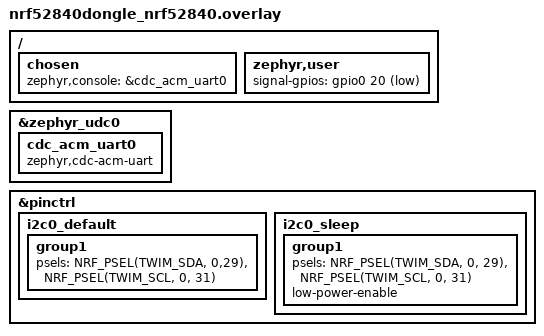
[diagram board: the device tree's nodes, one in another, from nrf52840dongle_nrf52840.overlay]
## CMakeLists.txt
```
#
# Copyright (c) 2018 Nordic Semiconductor
#
# SPDX-License-Identifier: LicenseRef-Nordic-5-Clause
#
cmake_minimum_required(VERSION 3.20.0)

set(PM_STATIC_YML_FILE
  ${CMAKE_CURRENT_SOURCE_DIR}/boards/pm_static_${BOARD}.yml
  )

find_package(Zephyr REQUIRED HINTS $ENV{ZEPHYR_BASE})
project(NONE)

target_sources(app PRIVATE src/max30102.c)

# NORDIC SDK APP START
target_sources(app PRIVATE
  src/main.c
)



# Preinitialization related to Thingy:53 DFU
target_sources_ifdef(CONFIG_BOARD_THINGY53_NRF5340_CPUAPP app PRIVATE  boards/thingy53.c)
target_sources_ifdef(CONFIG_BOARD_THINGY53_NRF5340_CPUAPP_NS app PRIVATE  boards/thingy53.c)

# NORDIC SDK APP END

zephyr_library_include_directories(.)
```

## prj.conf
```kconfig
#
# Copyright (c) 2018 Nordic Semiconductor
#
# SPDX-License-Identifier: LicenseRef-Nordic-5-Clause
#

# Enable the UART driver


# Make sure printk is printing to the UART console

CONFIG_USB_DEVICE_STACK=y
CONFIG_USB_DEVICE_PRODUCT="Zephyr USB console sample"

CONFIG_SERIAL=y
CONFIG_CONSOLE=y
CONFIG_UART_CONSOLE=y
CONFIG_UART_LINE_CTRL=y

#CONFIG_STDOUT_CONSOLE=y
#CONFIG_LOG=y
CONFIG_I2C=y

CONFIG_I2C=y
CONFIG_HEAP_MEM_POOL_SIZE=2048

CONFIG_BT=y
CONFIG_BT_PERIPHERAL=y
CONFIG_BT_DEVICE_NAME="Nordic_UART_Service"
CONFIG_BT_DEVICE_APPEARANCE=833
CONFIG_BT_MAX_CONN=1
CONFIG_BT_MAX_PAIRED=1
CONFIG_BT_NUS_SECURITY_ENABLED=n

# Enable the NUS service
CONFIG_BT_NUS=y

# Enable bonding
CONFIG_BT_SETTINGS=y
CONFIG_FLASH=y
CONFIG_FLASH_PAGE_LAYOUT=y
CONFIG_FLASH_MAP=y
CONFIG_NVS=y
CONFIG_SETTINGS=y


# This example requires more workqueue stack
CONFIG_SYSTEM_WORKQUEUE_STACK_SIZE=2048


# Config logger
CONFIG_LOG=y
CONFIG_USE_SEGGER_RTT=y
CONFIG_LOG_BACKEND_RTT=y
CONFIG_LOG_BACKEND_UART=y

CONFIG_ASSERT=y
```

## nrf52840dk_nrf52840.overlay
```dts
&pinctrl {
	i2c0_default: i2c0_default {
		group1 {
			psels = <NRF_PSEL(TWIM_SDA, 0,27)>,
				<NRF_PSEL(TWIM_SCL, 0, 26)>;
		};
	};

	i2c0_sleep: i2c0_sleep {
		group1 {
			psels = <NRF_PSEL(TWIM_SDA, 0, 27)>,
				<NRF_PSEL(TWIM_SCL, 0, 26)>;
			low-power-enable;
		};
	};
};
```

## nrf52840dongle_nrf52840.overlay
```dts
// To get started, press Ctrl+Space to bring up the completion menu and view the available nodes.

// You can also use the buttons in the sidebar to perform actions on nodes.
// Actions currently available include:

// * Enabling / disabling the node
// * Adding the bus to a bus
// * Removing the node
// * Connecting ADC channels

// For more help, browse the DeviceTree documentation at https://docs.zephyrproject.org/latest/guides/dts/index.html
// You can also visit the nRF DeviceTree extension documentation at https://nrfconnect.github.io/vscode-nrf-connect/devicetree/nrfdevicetree.html
/ {
	chosen {
		zephyr,console = &cdc_acm_uart0;
	};
	zephyr,user {
        signal-gpios = <&gpio0 20 (GPIO_PULL_UP | GPIO_ACTIVE_LOW)>;
    };
};

&zephyr_udc0 {
	cdc_acm_uart0: cdc_acm_uart0 {
		compatible = "zephyr,cdc-acm-uart";
	};
};


&pinctrl {
	i2c0_default: i2c0_default {
		group1 {
			psels = <NRF_PSEL(TWIM_SDA, 0,29)>,
				<NRF_PSEL(TWIM_SCL, 0, 31)>;
		};
	};

	i2c0_sleep: i2c0_sleep {
		group1 {
			psels = <NRF_PSEL(TWIM_SDA, 0, 29)>,
				<NRF_PSEL(TWIM_SCL, 0, 31)>;
			low-power-enable;
		};
	};
};
```

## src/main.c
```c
#include <zephyr.h>
#include <zephyr/types.h>
#include <zephyr/kernel.h>

#include <zephyr/device.h>
#include <zephyr/devicetree.h>
#include <soc.h>

#include <zephyr/bluetooth/bluetooth.h>
#include <zephyr/bluetooth/uuid.h>
#include <zephyr/bluetooth/gatt.h>
#include <zephyr/bluetooth/hci.h>

#include <bluetooth/services/nus.h>
#include <zephyr/settings/settings.h>
#include <zephyr/drivers/uart.h>
#include <zephyr/usb/usb_device.h>
#include <stdio.h>

#include <zephyr/logging/log.h>
#include "max30102.h"

#define LOG_MODULE_NAME bt_hr_sensor
LOG_MODULE_REGISTER(LOG_MODULE_NAME);

#define STACKSIZE CONFIG_BT_NUS_THREAD_STACK_SIZE
#define PRIORITY 7

#define DEVICE_NAME CONFIG_BT_DEVICE_NAME
#define DEVICE_NAME_LEN	(sizeof(DEVICE_NAME) - 1)


#define ZEPHYR_USER_NODE DT_PATH(zephyr_user)

static K_SEM_DEFINE(ble_init_ok, 0, 1);

K_FIFO_DEFINE(ppg_items);
K_SEM_DEFINE(sem_initialized_max30102, 0, 1);
K_SEM_DEFINE(sem_interruptmax30102, 0, 1);

const struct device *gpio0Port;	
struct gpio_callback interrupt_max30102;

static struct bt_conn *current_conn;
//static struct bt_conn *auth_conn;

static const struct bt_data ad[] = {
	BT_DATA_BYTES(BT_DATA_FLAGS, (BT_LE_AD_GENERAL | BT_LE_AD_NO_BREDR)),
	BT_DATA(BT_DATA_NAME_COMPLETE, DEVICE_NAME, DEVICE_NAME_LEN),
};

static const struct bt_data sd[] = {
	BT_DATA_BYTES(BT_DATA_UUID128_ALL, BT_UUID_NUS_VAL),
};

static const struct gpio_dt_spec signal = GPIO_DT_SPEC_GET(ZEPHYR_USER_NODE, signal_gpios);
BUILD_ASSERT(DT_NODE_HAS_COMPAT(DT_CHOSEN(zephyr_console), zephyr_cdc_acm_uart),
	     "Console device is not ACM CDC UART device");

static void connected(struct bt_conn *conn, uint8_t err)
{
	char addr[BT_ADDR_LE_STR_LEN];

	if (err) {
		LOG_ERR("Connection failed (err %u)", err);
		return;
	}

	bt_addr_le_to_str(bt_conn_get_dst(conn), addr, sizeof(addr));
	LOG_INF("Connected %s", addr);

	current_conn = bt_conn_ref(conn);	
}

static void disconnected(struct bt_conn *conn, uint8_t reason)
{
	char addr[BT_ADDR_LE_STR_LEN];

	bt_addr_le_to_str(bt_conn_get_dst(conn), addr, sizeof(addr));

	LOG_INF("Disconnected: %s (reason %u)", addr, reason);
	sys_reboot();
}



BT_CONN_CB_DEFINE(conn_callbacks) = {
	.connected    = connected,
	.disconnected = disconnected,

};

static void bt_receive_cb(struct bt_conn *conn, const uint8_t *const data,
			  uint16_t len)
{
	(void)conn;
	LOG_INF("Received data ");
}

static struct bt_nus_cb nus_cb = {
	.received = bt_receive_cb,
};

typedef struct {
    void *fifo_reserved;   /* 1st word reserved for use by FIFO */
    ppg_item_t ppgitem;
} fifo_item_t;

void max30102isr(const struct device *dev, struct gpio_callback *cb, uint32_t pins) {	
	k_sem_give(&sem_interruptmax30102);		
}

void attachinterrupt(void) {
	
	__ASSERT(device_is_ready(signal.port), "custom device not ready");
	gpio_pin_configure_dt(&signal, GPIO_INPUT);
	gpio_pin_interrupt_configure_dt(&signal, GPIO_INT_EDGE_TO_ACTIVE);
	gpio_init_callback(&interrupt_max30102, max30102isr, BIT(signal.pin));
	gpio_add_callback(signal.port, &interrupt_max30102);	
}


void main(void)
{	
	//const struct device *dev = DEVICE_DT_GET(DT_CHOSEN(zephyr_console));
	//uint32_t dtr = 0;

	if (usb_enable(NULL)) {
		return;
	}

	/* Poll if the DTR flag was set */
	// while (!dtr) {
	// 	uart_line_ctrl_get(dev, UART_LINE_CTRL_DTR, &dtr);
	// 	/* Give CPU resources to low priority threads. */
	// 	k_sleep(K_MSEC(100));
	// }


	int err = 0;	

	err = bt_enable(NULL);	

	LOG_INF("Bluetooth initialized");	

	if (IS_ENABLED(CONFIG_SETTINGS)) {
		settings_load();
	}

	err = bt_nus_init(&nus_cb);
	if (err) {
		LOG_ERR("Failed to initialize UART service (err: %d)", err);
		return;
	}

	err = bt_le_adv_start(BT_LE_ADV_CONN, ad, ARRAY_SIZE(ad), sd,
			      ARRAY_SIZE(sd));
	if (err) {
		LOG_ERR("Advertising failed to start (err %d)", err);
		return;
	}


	LOG_INF("interrupt-attached");

	if(max30102_init()) {
		LOG_ERR("could not initialize");
		k_sleep(K_FOREVER);		
	}	
	attachinterrupt();
	uint8_t max_read_state = max30102_interrupt_state(); //clear interrupt;

	LOG_INF("max initialized, read state:%i", max_read_state);
	
	
	k_sem_give(&sem_initialized_max30102);

	k_sem_give(&ble_init_ok);
	LOG_INF("bt-enabled");

	for (;;) {		
		k_sleep(K_MSEC(2000));
		LOG_INF("alive");
	}
}

void nus_fifo_service(void)
{	
	/* Don't go any further until BLE is initialized */
	k_sem_take(&ble_init_ok, K_FOREVER);
	char buffer[sizeof(ppg_item_t)];
	
	for (;;) {
		
		fifo_item_t *package;
		package = k_fifo_get(&ppg_items, K_FOREVER);
		ppg_item_t ppgitem = package->ppgitem;	
		memcpy(buffer, (uint8_t*)&ppgitem, sizeof(ppg_item_t));
		if (bt_nus_send(NULL, buffer, sizeof(ppg_item_t))) {
			LOG_WRN("Failed to send data over BLE connection");
		} else {			
			LOG_INF("send ppg ir=%d, red=%d", ppgitem.ir, ppgitem.red);
		}
		k_free(package);
	}
}

void max30102read(void) {	
	k_sem_take(&sem_initialized_max30102, K_FOREVER);
	
	uint8_t amount_samples;
	uint8_t isrstate;
	ppg_item_t buffer[32]; //maximum amount for ic
	
	while (1) {		
		k_sem_take(&sem_interruptmax30102, K_MSEC(5000));
		isrstate = max30102_interrupt_state();
		if (isrstate != 0b10000000) {
			LOG_WRN("unexpected max30102int: %d", isrstate);	
		} 
		amount_samples = GetSamplesAvailable();		
		
		max30102data(buffer, amount_samples);
		
		for (int i = 0; i < amount_samples; i++)
		{			
			fifo_item_t *toqueue = k_malloc(sizeof(fifo_item_t));
			toqueue->ppgitem = buffer[i];			
			k_fifo_put(&ppg_items, toqueue);
		} 			
	}
}

K_THREAD_DEFINE(max30102_read_thread_id, 1024, max30102read, NULL, NULL,
		NULL, 7, 0, 0);

K_THREAD_DEFINE(nus_fifo_service_id, STACKSIZE, nus_fifo_service, NULL, NULL,
		NULL, 8, 0, 0);
```

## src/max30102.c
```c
/*
 * Copyright (c) 2017, NXP
 *
 * SPDX-License-Identifier: Apache-2.0
 */
//#define DT_DRV_COMPAT maxim_max30101

#include <zephyr.h>
#include <stdio.h>
#include <logging/log.h>
#include "max30102.h"

#define register_count 9
#define led_channels 1

const struct device *i2c;


max30102_config max30102cfg = {
// 	.i2c_label = DT_INST_PROP(0, label),
 	.i2c_addr = 0x57// DT_INST_REG_ADDR(0),
};



LOG_MODULE_REGISTER(MAX30102, 0);

int GetSamplesAvailable()
{
	uint8_t fifo_wr_ptr;
	uint8_t fifo_rd_ptr;
	int samples_avalable = 0;

	int wr = i2c_reg_read_byte(i2c, max30102cfg.i2c_addr, 0x04, &fifo_wr_ptr);
	int rd = i2c_reg_read_byte(i2c, max30102cfg.i2c_addr, 0x06, &fifo_rd_ptr);
	if(wr || rd) {
		LOG_ERR("max30102 read or write pointer error");
		return 0;
	}

	if (fifo_wr_ptr != fifo_rd_ptr)
	{
		samples_avalable = fifo_wr_ptr - fifo_rd_ptr;
		if (samples_avalable < 0) {
			samples_avalable += 32; // wrap condition>		
		}
	}	
	return samples_avalable;
}

float temperature(void)
{
	uint8_t temperature;
	uint8_t fraction;
	i2c_reg_read_byte(i2c, max30102cfg.i2c_addr, 0x1F, &temperature);
	i2c_reg_read_byte(i2c, max30102cfg.i2c_addr, 0x20, &fraction);
	if (temperature > 0x7F)
	{
		temperature = -0xFF + (temperature - 1);
	}
	// enable temperature
	i2c_reg_write_byte(i2c, max30102cfg.i2c_addr, 0x21, 1);
	return (float)temperature + fraction * 0.0625;
}


int fetch_max30102(uint32_t * samplebuffer, int samplesToTake)
{
	if (samplesToTake == 0) return 0;	
	
	uint32_t fifo_data;
	int num_bytes = 3 * led_channels * samplesToTake; //2 channels, 3 bytes each
	uint8_t buffer[num_bytes];

	/* Read all the active channels for all samples */		 
	if (i2c_burst_read(i2c, max30102cfg.i2c_addr, 0x07, buffer, num_bytes))
	{
		LOG_ERR("could not read sample");
		return 1;
	}
	
	for (uint32_t y = 0; y < (samplesToTake * led_channels); y++)
	{				
		/* Each channel sample is 18-bits */
		fifo_data = (buffer[y*3] << 16) | (buffer[y*3 + 1] << 8) |
					(buffer[y*3 + 2]);
		fifo_data &= MAX30102_FIFO_DATA_MASK;

		samplebuffer[y] = fifo_data;
	}

	return 0;
}

int max30102data(ppg_item_t * ppg_items, int samplesToTake) {
	int buffersize = samplesToTake * led_channels;
	uint32_t buffer[buffersize]; //two led colors
	if(fetch_max30102(buffer, samplesToTake)){
		return 1;
	}
	unsigned int pic = 0; //ppg item count
	for (size_t i = 0; i < buffersize; i+=led_channels)
	{				
		ppg_items[pic].ir = buffer[i];
#if(led_channels > 1)
		ppg_items[pic].red = buffer[i+1];	
#else
		ppg_items[pic].red = 0;	
#endif
		pic++;
	}
	return 0;
}

uint8_t max30102_interrupt_state() {
	uint8_t status;
	i2c_reg_read_byte(i2c, max30102cfg.i2c_addr, 0x00, &status);
	return status;
}

int safewriteconfig(uint8_t reg, uint8_t value) {
	if (i2c_reg_write_byte(i2c, max30102cfg.i2c_addr, reg,value))
	{
		LOG_ERR("couldn't write to 0x%02x", reg);
		return -EIO;
	}
	return 0;
}

int max30102_init()
{
	uint8_t part_id;
	uint8_t mode_cfg;

	/* Get the I2C device */	
	i2c = DEVICE_DT_GET(DT_NODELABEL(i2c0));
	__ASSERT(device_is_ready(i2c), "max30102 device not ready");
	
	

	/* Check the part id to make sure this is MAX30102 */
	if (i2c_reg_read_byte(i2c, max30102cfg.i2c_addr,
						  MAX30102_REG_PART_ID, &part_id))
	{
		LOG_ERR("Could not get Part ID");
		return -EIO;
	}
	if (part_id != MAX30102_PART_ID)
	{
		LOG_ERR("Got Part ID 0x%02x, expected 0x%02x",
				part_id, MAX30102_PART_ID);
		return -EIO;
	}
	else
	{
		LOG_INF("Got Part ID 0x%02x as expected", part_id);
	}

	/* Reset the sensor */
	if (i2c_reg_write_byte(i2c, max30102cfg.i2c_addr,
						   MAX30102_REG_MODE_CFG,
						   MAX30102_MODE_CFG_RESET_MASK))
	{
		return -EIO;
	}

	/* Wait for reset to be cleared */
	do
	{
		if (i2c_reg_read_byte(i2c, max30102cfg.i2c_addr,
							  MAX30102_REG_MODE_CFG, &mode_cfg))
		{
			LOG_ERR("Could read mode cfg after reset");
			return -EIO;
		}
	} while (mode_cfg & MAX30102_MODE_CFG_RESET_MASK);
	
	uint8_t regsettings[register_count][2] = {
			//Interrupt Enable
			{0x02, 0b10000000},
			//DIE_TEMP_RDY_EN = false
			{0x03, 0b00000000},
			//FIFO config - average, yes rollover, fifo almost full @ 4 left	
			{0x08, 0b11111111},
			// mode configuration
			{0x09, 0b00000010},
			//Sample Rate Control
			{0x0A, 0b01110111},
			//LED pulse amplitude 
			{0x0C, 0x7f},  	//red
			{0x0D, 0x7f},	//ir
			//multi-LED mode control 
			{0x11, 0b00000010},
			{0x12, 0b00000000}
		};		
	
	for (size_t i = 0; i < register_count; i++)
	{		
		if(safewriteconfig(regsettings[i][0], regsettings[i][1])) {
			return -EIO;
		}
	}

	return 0;
}
```
